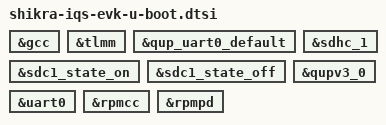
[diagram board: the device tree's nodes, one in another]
// SPDX-License-Identifier: BSD-3-Clause
/*
 * Copyright (c) Qualcomm Technologies, Inc. and/or its subsidiaries.
 */

/* Keep the console and QUPFW storage paths in the SPL device tree. */
&gcc {
	bootph-all;
};

&tlmm {
	bootph-all;
};

&qup_uart0_default {
	bootph-all;
};

&sdc1_state_on {
	bootph-all;
};

&sdc1_state_off {
	bootph-all;
};

&sdhc_1 {
	bootph-all;
};

&qupv3_0 {
	bootph-all;
};

&uart0 {
	bootph-all;
};

/* Retain the RPM clock and power-domain providers for boot consumers. */
&rpmcc {
	bootph-all;
};

&rpmpd {
	bootph-all;
};
